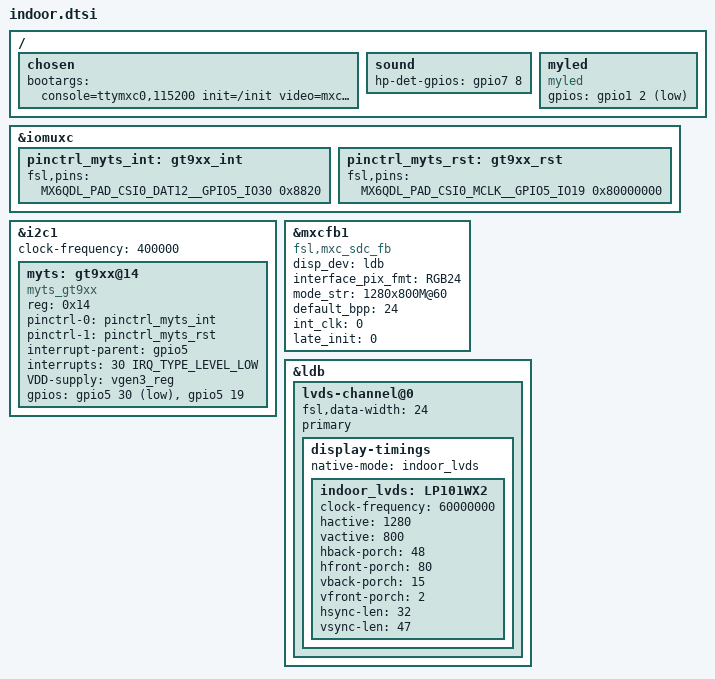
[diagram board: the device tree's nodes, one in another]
/ {
	chosen {
		bootargs = "console=ttymxc0,115200 init=/init video=mxcfb0:dev=ldb,LDBXGA,if=RGB24,bpp=18 ldb=sin0 video=mxcfb1:off video=mxcfb2:off fbmem=10M fb0base=0x27b00000 vmalloc=400M androidboot.console=ttymxc0 androidboot.hardware=freescale androidboot.selinux=disabled androidboot.dm_verity=disabled";
	};

	sound {
		hp-det-gpios = <&gpio7 8 0>;
	};
	
	myled {
		compatible = "myled";
		gpios = <&gpio1 2 GPIO_ACTIVE_LOW>;
	};
};

&iomuxc {
	pinctrl_myts_int: gt9xx_int {
		fsl,pins = <MX6QDL_PAD_CSI0_DAT12__GPIO5_IO30 0x8820>;
	};

	pinctrl_myts_rst: gt9xx_rst {
		fsl,pins = <MX6QDL_PAD_CSI0_MCLK__GPIO5_IO19 0x80000000>;
	};
};

&i2c1 {
	clock-frequency = <400000>;
	myts: gt9xx@14 {
		compatible = "myts_gt9xx";
		reg = <0x14>;
		pinctrl-names = "int_pin", "rst_pin";
		pinctrl-0 = <&pinctrl_myts_int>;
		pinctrl-1 = <&pinctrl_myts_rst>;

		interrupt-parent = <&gpio5>;
		interrupts = <30 IRQ_TYPE_LEVEL_LOW>;

		VDD-supply = <&vgen3_reg>;
		gpios = <&gpio5 30 GPIO_ACTIVE_LOW
				 &gpio5 19 GPIO_ACTIVE_HIGH>;
	};
};

&mxcfb1 {
	compatible = "fsl,mxc_sdc_fb";
	disp_dev = "ldb";
	interface_pix_fmt = "RGB24";
	mode_str ="1280x800M@60";
	default_bpp = <24>;
	int_clk = <0>;
	late_init = <0>;
	status = "ok";
};

&ldb {
	lvds-channel@0 {
		fsl,data-width = <24>;
		primary;

		display-timings {
			native-mode = <&indoor_lvds>;
			indoor_lvds: LP101WX2 {
				clock-frequency = <60000000>;
				hactive = <1280>;
				vactive = <800>;
				hback-porch = <48>;
				hfront-porch = <80>;
				vback-porch = <15>;
				vfront-porch = <2>;
				hsync-len = <32>;
				vsync-len = <47>;
			};
		};
	};
};
